# LPC845 register map
Vendor: nxp.com; File version: 1.0
CPU: CM0PLUS r0p0, little endian, no MPU, no FPU, VTOR, 2 interrupt priority bits
Registers are 32-bit, read-write, reset 0x0 unless marked. A register's access mark holds for its fields unless they carry their own. Offsets are from the block's base; [hi:lo] are bit positions.

## WKT — LPC84x Wake Up Timer(WKT)
Base 0x40008000
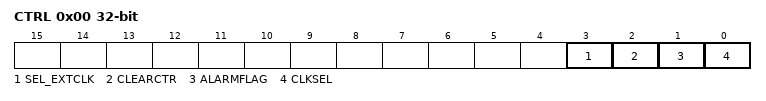
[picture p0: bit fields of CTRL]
0x00 CTRL — Self wake-up timer control register.
  [3] SEL_EXTCLK — Select external or internal clock source for the self wake-up timer. The internal clock source is selected by the CLKSEL bit in this register if SET_EXTCLK is set to internal.
    0=INTERNAL (Internal. The clock source is the internal clock selected by the CLKSEL bit.); 1=EXTERNAL (External. The self wake-up timer uses the external WKTCLKIN pin.)
  [2] CLEARCTR — Clears the self wake-up timer.
    0=NO_EFFECT (No effect. Reading this bit always returns 0.); 1=CLEAR_THE_COUNTER (Clear the counter. Counting is halted until a new count value is loaded.)
  [1] ALARMFLAG — Wake-up or alarm timer flag.
    0=NO_TIME_OUT (No time-out. The self wake-up timer has not timed out. Writing a 0 to has no effect.); 1=TIME_OUT (Time-out. The self wake-up timer has timed out. This flag generates an interrupt request which can wake up the part from any reduced power mode including Deep power-down if the clock source is the low power oscillator. Writing a 1 clears this status bit.)
  [0] CLKSEL — Select the self wake-up timer clock source. Remark: This bit only has an effect if the SEL_EXTCLK bit is not set.
    0=DIVIDED_FRO_CLOCK (Divided FRO clock. This clock runs at 750 kHz and provides time-out periods of up to approximately 95 minutes in 1.33 us increments. Remark: This clock is not available in not available in Deep-sleep, power-down, deep power-down modes. Do not select this option if the timer is to be used to wake up from one of these modes.); 1=LOW_POWER_CLOCK (This is the (nominally) 10 kHz clock and provides time-out periods of up to approximately 119 hours in 100 us increments. The accuracy of this clock is limited to +/- 40 % over temperature and processing. Remark: This clock is available in all power modes. Prior to use, the low-power oscillator must be enabled. The oscillator must also be set to remain active in Deep power-down if needed.)
0x0C COUNT reset not defined — Counter register.
  [31:0] VALUE — A write to this register pre-loads start count value into the timer and starts the count-down sequence. A read reflects the current value of the timer.

## DAC0 — LPC84x 10-bit DAC controller (DAC)
Base 0x40014000
Same registers: DAC1 0x40018000
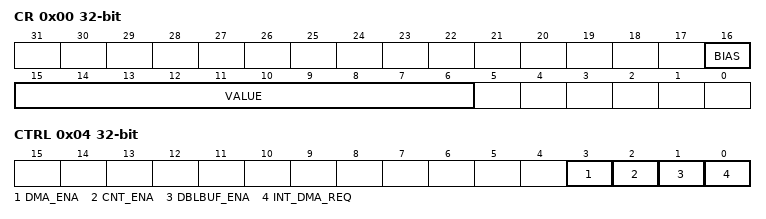
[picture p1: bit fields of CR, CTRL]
0x00 CR — D/A Converter Register. This register contains the digital value to be converted to analog and a power control bit.
  [16] BIAS — The settling time of the DAC
    0=The settling time of the DAC is 1 us max, and the maximum current is 700 uA. This allows a maximum update rate of 1 MHz.; 1=The settling time of the DAC is 2.5 us and the maximum current is 350 uA. This allows a maximum update rate of 400 kHz.
  [15:6] VALUE — After the selected settling time after this field is written with a new VALUE, the voltage on the DAC_OUT pin (with respect to VSSA) is VALUE (VREFP - VREFN)/1024 + VREFN.
0x04 CTRL — DAC Control register. This register controls DMA and timer operation.
  [3] DMA_ENA — DMA access
    0=DISABLED (DMA access is disabled.); 1=ENABLED (DMA Burst Request Input 7 is enabled for the DAC)
  [2] CNT_ENA — time-out counter operation
    0=DISABLED (Time-out counter operation is disabled.); 1=ENABLED (Time-out counter operation is enabled.)
  [1] DBLBUF_ENA — dacr double buffer
    0=DISABLED (DACR double-buffering is disabled.); 1=ENABLED (When this bit and the CNT_ENA bit are both set, the double-buffering feature in the DACR register will be enabled. Writes to the DACR register are written to a pre-buffer and then transferred to the DACR on the next time-out of the counter.)
  [0] INT_DMA_REQ — DMA request
    0=CLEAR (This bit is cleared on any write to the DACR register.); 1=SET (This bit is set by hardware when the timer times out.)
0x08 CNTVAL — DAC Counter Value register. This register contains the reload value for the DAC DMA/Interrupt timer.
  [15:0] VALUE — 16-bit reload value for the DAC interrupt/DMA timer.
